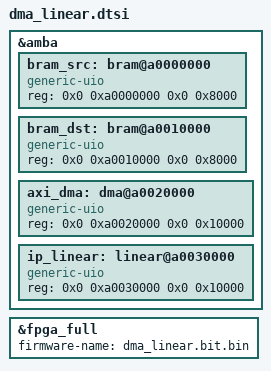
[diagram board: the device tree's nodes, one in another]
/dts-v1/;
/plugin/;

/ {
    fragment@0 {
        target = <&amba>;
        __overlay__ {
            #address-cells = <2>;
            #size-cells = <2>;
            
            bram_src: bram@a0000000 {
                compatible = "generic-uio";
                reg = <0x0 0xa0000000 0x0 0x8000>;
            };
            
            bram_dst: bram@a0010000 {
                compatible = "generic-uio";
                reg = <0x0 0xa0010000 0x0 0x8000>;
            };

            axi_dma: dma@a0020000 {
                compatible = "generic-uio";
                reg = <0x0 0xa0020000 0x0 0x10000>;
            };
            
            ip_linear: linear@a0030000 {
                compatible = "generic-uio";
                reg = <0x0 0xa0030000 0x0 0x10000>;
            };
        };
    };
    fragment@1 {
        target = <&fpga_full>;
        __overlay__ {
            #address-cells = <2>;
            #size-cells = <2>;
            /* Đảm bảo tên này khớp với file bitstream của bạn trên mạch */
            firmware-name = "dma_linear.bit.bin";
        };
    };
};
